# AT32F421xx register map
Vendor: Keil; Series: AT32F421; File version: 1.0
CPU: CM4 r0p1, little endian, no MPU, FPU, 4 interrupt priority bits
Registers are 32-bit, read-write, reset 0x0 unless marked. A register's access mark holds for its fields unless they carry their own. Offsets are from the block's base; [hi:lo] are bit positions.

## RCC — Reset and clock control
Base 0x40021000
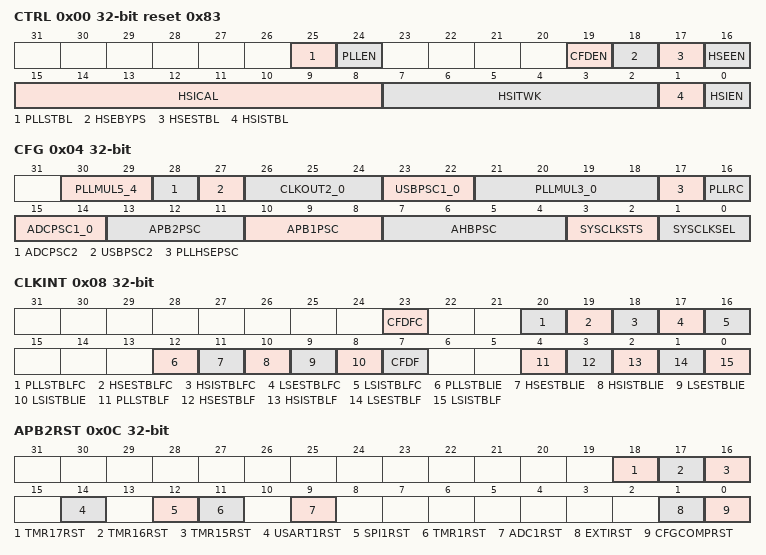
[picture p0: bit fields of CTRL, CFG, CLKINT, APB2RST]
0x00 CTRL reset 0x83 — Clock control register
  [25] PLLSTBL ro — PLL clock ready flag
  [24] PLLEN — PLL enable
  [19] CFDEN — Clock Failure Detection enable
  [18] HSEBYPS — External High Speed clock Bypass
  [17] HSESTBL ro — External High Speed clock ready flag
  [16] HSEEN — External High Speed clock enable
  [15:8] HSICAL ro — Internal High Speed clock Calibration
  [7:2] HSITWK — Internal High Speed clock trimming
  [1] HSISTBL ro — Internal High Speed clock ready flag
  [0] HSIEN — Internal High Speed clock enable
0x04 CFG — Clock configuration register (RCC_CFG)
  [30:29] PLLMUL5_4 — PLLMUL bit5 and bit4
  [28] ADCPSC2 — ADC prescaler bit2
  [27] USBPSC2 — USB prescaler bit2
  [26:24] CLKOUT2_0 — Microcontroller clock output bit2 to bit0
  [23:22] USBPSC1_0 — USB prescaler bit1 and bit0
  [21:18] PLLMUL3_0 — PLL Multiplication Factor bit3 to bit0
  [17] PLLHSEPSC — HSE divider for PLL entry
  [16] PLLRC — PLL entry clock source
  [15:14] ADCPSC1_0 — ADC prescaler bit1 and bit0
  [13:11] APB2PSC — APB High speed prescaler (APB2)
  [10:8] APB1PSC — APB Low speed prescaler (APB1)
  [7:4] AHBPSC — AHB prescaler
  [3:2] SYSCLKSTS ro — System Clock Switch Status
  [1:0] SYSCLKSEL — System clock Switch
0x08 CLKINT — Clock interrupt register (RCC_CLKINT)
  [23] CFDFC wo — Clock Failure Detection interrupt clear
  [20] PLLSTBLFC wo — PLL Ready Interrupt Clear
  [19] HSESTBLFC wo — HSE Ready Interrupt Clear
  [18] HSISTBLFC wo — HSI Ready Interrupt Clear
  [17] LSESTBLFC wo — LSE Ready Interrupt Clear
  [16] LSISTBLFC wo — LSI Ready Interrupt Clear
  [12] PLLSTBLIE — PLL Ready Interrupt Enable
  [11] HSESTBLIE — HSE Ready Interrupt Enable
  [10] HSISTBLIE — HSI Ready Interrupt Enable
  [9] LSESTBLIE — LSE Ready Interrupt Enable
  [8] LSISTBLIE — LSI Ready Interrupt Enable
  [7] CFDF ro — Clock Failure Detection interrupt flag
  [4] PLLSTBLF ro — PLL Ready Interrupt flag
  [3] HSESTBLF ro — HSE Ready Interrupt flag
  [2] HSISTBLF ro — HSI Ready Interrupt flag
  [1] LSESTBLF ro — LSE Ready Interrupt flag
  [0] LSISTBLF ro — LSI Ready Interrupt flag
0x0C APB2RST — APB2 peripheral reset register (RCC_APB2RST)
  [18] TMR17RST — TIM11 timer reset
  [17] TMR16RST — TIM10 timer reset
  [16] TMR15RST — TIM9 timer reset
  [14] USART1RST — USART1 reset
  [12] SPI1RST — SPI 1 reset
  [11] TMR1RST — TIM1 timer reset
  [9] ADC1RST — ADC 1 interface reset
  [1] EXTIRST — EXTI reset
  [0] CFGCOMPRST — SYSCFG and COMP reset
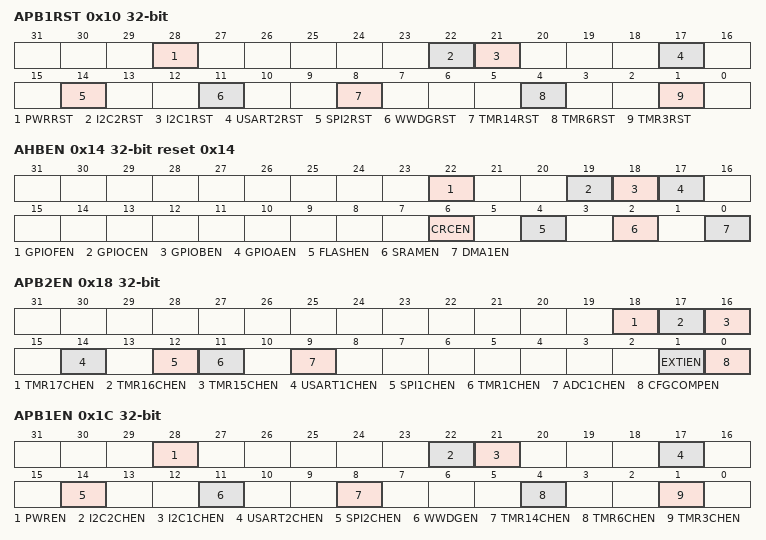
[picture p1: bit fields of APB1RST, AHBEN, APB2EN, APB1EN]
0x10 APB1RST — APB1 peripheral reset register (RCC_APB1RST)
  [28] PWRRST — Power interface reset
  [22] I2C2RST — I2C2 reset
  [21] I2C1RST — I2C1 reset
  [17] USART2RST — USART 2 reset
  [14] SPI2RST — SPI2 reset
  [11] WWDGRST — Window watchdog reset
  [8] TMR14RST — Timer 14 reset
  [4] TMR6RST — Timer 6 reset
  [1] TMR3RST — Timer 3 reset
0x14 AHBEN reset 0x14 — AHB Peripheral Clock enable register (RCC_AHBEN)
  [22] GPIOFEN — GPIOA clock enable
  [19] GPIOCEN — GPIOA clock enable
  [18] GPIOBEN — GPIOA clock enable
  [17] GPIOAEN — GPIOA clock enable
  [6] CRCEN — CRC clock enable
  [4] FLASHEN — FLASH clock enable
  [2] SRAMEN — SRAM interface clock enable
  [0] DMA1EN — DMA1 clock enable
0x18 APB2EN — APB2 peripheral clock enable register (RCC_APB2EN)
  [18] TMR17CHEN — Timer 17 clock enable
  [17] TMR16CHEN — Timer 16 clock enable
  [16] TMR15CHEN — Timer 15 clock enable
  [14] USART1CHEN — USART1 clock enable
  [12] SPI1CHEN — SPI 1 clock enable
  [11] TMR1CHEN — Timer 1 clock enable
  [9] ADC1CHEN — ADC 1 interface clock enable
  [1] EXTIEN — EXTI clock enable
  [0] CFGCOMPEN — SYSCFG and COMP clock enable
0x1C APB1EN — APB1 peripheral clock enable register (RCC_APB1EN)
  [28] PWREN — Power interface clock enable
  [22] I2C2CHEN — I2C 2 clock enable
  [21] I2C1CHEN — I2C1 clock enable
  [17] USART2CHEN — USART 2 clock enable
  [14] SPI2CHEN — SPI 2 clock enable
  [11] WWDGEN — Window watchdog clock enable
  [8] TMR14CHEN — Timer 14 clock enable
  [4] TMR6CHEN — Timer 5 clock enable
  [1] TMR3CHEN — Timer 3 clock enable
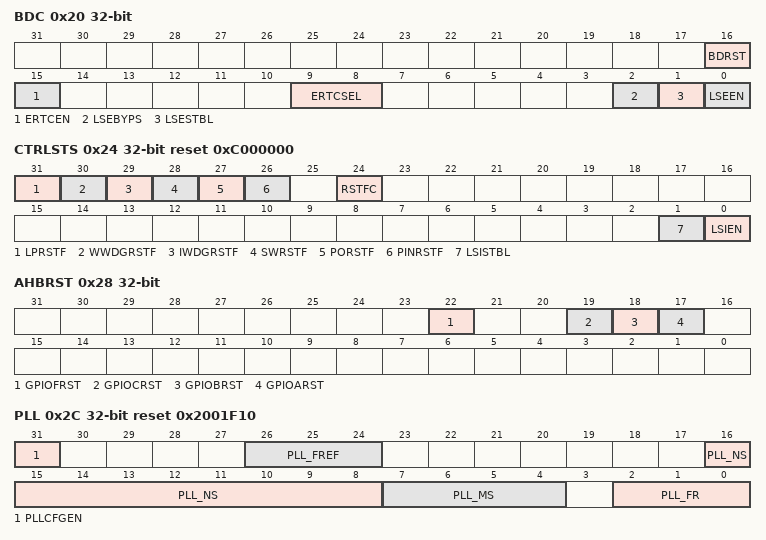
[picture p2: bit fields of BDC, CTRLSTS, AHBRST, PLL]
0x20 BDC — Backup domain control register (RCC_BDC)
  [16] BDRST — Backup domain software reset
  [15] ERTCEN — ERTC clock enable
  [9:8] ERTCSEL — ERTC clock source selection
  [2] LSEBYPS — External Low Speed oscillator bypass
  [1] LSESTBL ro — External Low Speed oscillator ready
  [0] LSEEN — External Low Speed oscillator enable
0x24 CTRLSTS reset 0xC000000 — Control/status register (RCC_CTRLSTS)
  [31] LPRSTF — Low-power reset flag
  [30] WWDGRSTF — Window watchdog reset flag
  [29] IWDGRSTF — Independent watchdog reset flag
  [28] SWRSTF — Software reset flag
  [27] PORSTF — POR/PDR reset flag
  [26] PINRSTF — PIN reset flag
  [24] RSTFC — Remove reset flag
  [1] LSISTBL ro — Internal low speed oscillator ready
  [0] LSIEN — Internal low speed oscillator enable
0x28 AHBRST — AHB peripheral reset register (RCC_AHBRST)
  [22] GPIOFRST — GPIOF reset
  [19] GPIOCRST — GPIOC reset
  [18] GPIOBRST — GPIOB reset
  [17] GPIOARST — GPIOA reset
0x2C PLL reset 0x2001F10 — PLL Configure register (RCC_PLL)
  [31] PLLCFGEN — PLL Configure Enable
  [26:24] PLL_FREF — PLL Configuration Table
  [16:8] PLL_NS — PLL NS Configuration Value
  [7:4] PLL_MS — PLL MS Configuration Value
  [2:0] PLL_FR — PLL FR Configuration Value
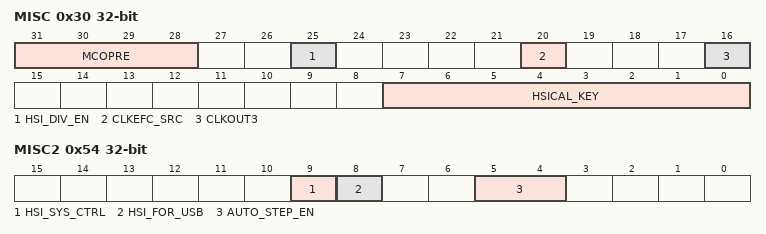
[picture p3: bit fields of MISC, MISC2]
0x30 MISC — RCC external register (RCC_MISC)
  [31:28] MCOPRE — Microcontroller clock output pre-divider
  [25] HSI_DIV_EN — HSI divider 6 enable
  [20] CLKEFC_SRC
  [16] CLKOUT3 — CLKOUT bit3
  [7:0] HSICAL_KEY — HSICAL write key value
0x54 MISC2 — RCC external register2 (RCC_MISC2)
  [9] HSI_SYS_CTRL, [8] HSI_FOR_USB, [5:4] AUTO_STEP_EN

## Notices in the file
Copyright (C) 2012-2014 ARM Limited. All rights reserved.
Purpose: System Viewer Description (SVD) Example (Schema Version 1.1)
This is a description of a none-existent and incomplete device
for demonstration purposes only.
Redistribution and use in source and binary forms, with or without
modification, are permitted provided that the following conditions are met:
- Redistributions of source code must retain the above copyright
notice, this list of conditions and the following disclaimer.
- Redistributions in binary form must reproduce the above copyright
notice, this list of conditions and the following disclaimer in the
documentation and/or other materials provided with the distribution.
- Neither the name of ARM nor the names of its contributors may be used
to endorse or promote products derived from this software without
specific prior written permission.
THIS SOFTWARE IS PROVIDED BY THE COPYRIGHT HOLDERS AND CONTRIBUTORS "AS IS"
AND ANY EXPRESS OR IMPLIED WARRANTIES, INCLUDING, BUT NOT LIMITED TO, THE
IMPLIED WARRANTIES OF MERCHANTABILITY AND FITNESS FOR A PARTICULAR PURPOSE
ARE DISCLAIMED. IN NO EVENT SHALL COPYRIGHT HOLDERS AND CONTRIBUTORS BE
LIABLE FOR ANY DIRECT, INDIRECT, INCIDENTAL, SPECIAL, EXEMPLARY, OR
CONSEQUENTIAL DAMAGES (INCLUDING, BUT NOT LIMITED TO, PROCUREMENT OF
SUBSTITUTE GOODS OR SERVICES; LOSS OF USE, DATA, OR PROFITS; OR BUSINESS
INTERRUPTION) HOWEVER CAUSED AND ON ANY THEORY OF LIABILITY, WHETHER IN
CONTRACT, STRICT LIABILITY, OR TORT (INCLUDING NEGLIGENCE OR OTHERWISE)
ARISING IN ANY WAY OUT OF THE USE OF THIS SOFTWARE, EVEN IF ADVISED OF THE
POSSIBILITY OF SUCH DAMAGE.
